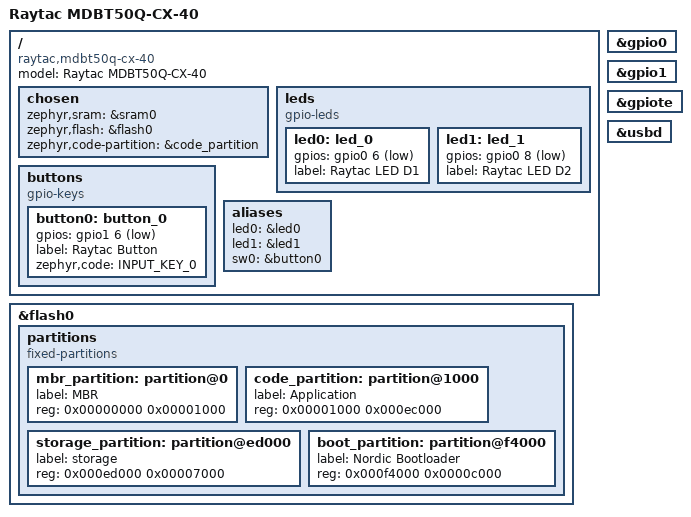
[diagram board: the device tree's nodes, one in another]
/* Raytac MDBT50Q-CX-40 USB-C dongle / nRF52840 */
/dts-v1/;
#include <nordic/nrf52840_qiaa.dtsi>
#include <zephyr/dt-bindings/input/input-event-codes.h>
#include <zephyr/dt-bindings/gpio/gpio.h>

/ {
    model = "Raytac MDBT50Q-CX-40";
    compatible = "raytac,mdbt50q-cx-40";

    chosen {
        zephyr,sram = &sram0;
        zephyr,flash = &flash0;
        zephyr,code-partition = &code_partition;
    };

    leds {
        compatible = "gpio-leds";
        led0: led_0 { gpios = <&gpio0 6 GPIO_ACTIVE_LOW>; label = "Raytac LED D1"; };
        led1: led_1 { gpios = <&gpio0 8 GPIO_ACTIVE_LOW>; label = "Raytac LED D2"; };
    };

    buttons {
        compatible = "gpio-keys";
        button0: button_0 { gpios = <&gpio1 6 (GPIO_ACTIVE_LOW | GPIO_PULL_UP)>; label = "Raytac Button"; zephyr,code = <INPUT_KEY_0>; };
    };

    aliases { led0 = &led0; led1 = &led1; sw0 = &button0; };
};

&gpio0 { status = "okay"; };
&gpio1 { status = "okay"; };
&gpiote { status = "okay"; };
&usbd { status = "okay"; };

/* Retain the stock Nordic serial DFU bootloader. Do NOT flash a full-chip image. */
&flash0 {
    partitions {
        compatible = "fixed-partitions";
        #address-cells = <1>;
        #size-cells = <1>;

        mbr_partition: partition@0 { label = "MBR"; reg = <0x00000000 0x00001000>; };
        code_partition: partition@1000 { label = "Application"; reg = <0x00001000 0x000ec000>; };
        storage_partition: partition@ed000 { label = "storage"; reg = <0x000ed000 0x00007000>; };
        boot_partition: partition@f4000 { label = "Nordic Bootloader"; reg = <0x000f4000 0x0000c000>; };
    };
};
